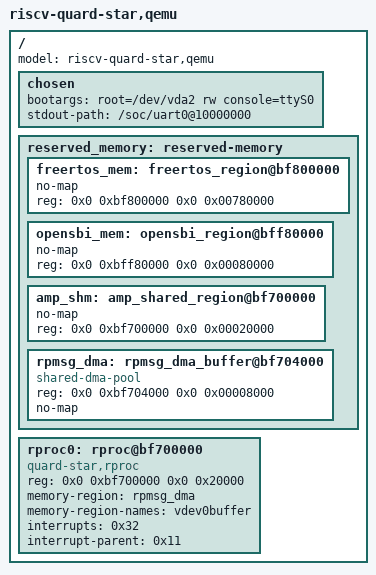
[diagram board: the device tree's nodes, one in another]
/* riscv-quard-star-uboot.dts */

/dts-v1/;

/include/ "riscv-quard-star-soc.dtsi"

/ {
    model = "riscv-quard-star,qemu";

    chosen {
        bootargs = "root=/dev/vda2 rw console=ttyS0";
        stdout-path = "/soc/uart0@10000000";
    };

    reserved_memory: reserved-memory {
        #address-cells = <0x2>;
        #size-cells = <0x2>;
        ranges;

        /* 1. 保护 FreeRTOS 的运行空间 (Hart 7) */
        freertos_mem: freertos_region@bf800000 {
            no-map;
            reg = <0x0 0xbf800000 0x0 0x00780000>;
        };

        /* 2. 保护 OpenSBI 的固件空间 */
        opensbi_mem: opensbi_region@bff80000 {
            no-map;
            reg = <0x0 0xbff80000 0x0 0x00080000>;
        };

        /* 3. 保护 OpenAMP 共享内存整体区域（防止其他驱动占用） */
        amp_shm: amp_shared_region@bf700000 {
            no-map;
            reg = <0x0 0xbf700000 0x0 0x00020000>;
        };

        /* 4. RPMsg buffer DMA 池（给 virtio_rpmsg_bus 使用） */
        /* virtio_rpmsg_bus 会从这里分配 DMA buffer */
        rpmsg_dma: rpmsg_dma_buffer@bf704000 {
            compatible = "shared-dma-pool";
            reg = <0x0 0xbf704000 0x0 0x00008000>;  /* 32KB @ 0xbf704000 */
            no-map;
        };
    };

    /* Remoteproc for FreeRTOS Domain (Hart 7) */
    rproc0: rproc@bf700000 {
        compatible = "quard-star,rproc";
        reg = <0x0 0xbf700000 0x0 0x20000>;
        /* 引用上面定义好的共享内存（可选，用于资源表定位） */
        memory-region = <&rpmsg_dma>;
        /* 关键：名字必须为 "vdev0buffer"，remoteproc 核心会自动查找并绑定给 virtio */
        memory-region-names = "vdev0buffer";
        /* Mailbox IRQ 50 for notifications from FreeRTOS (Hart 7) */
        interrupts = <0x32>;
        interrupt-parent = <0x11>;
        status = "okay";
    };
};
